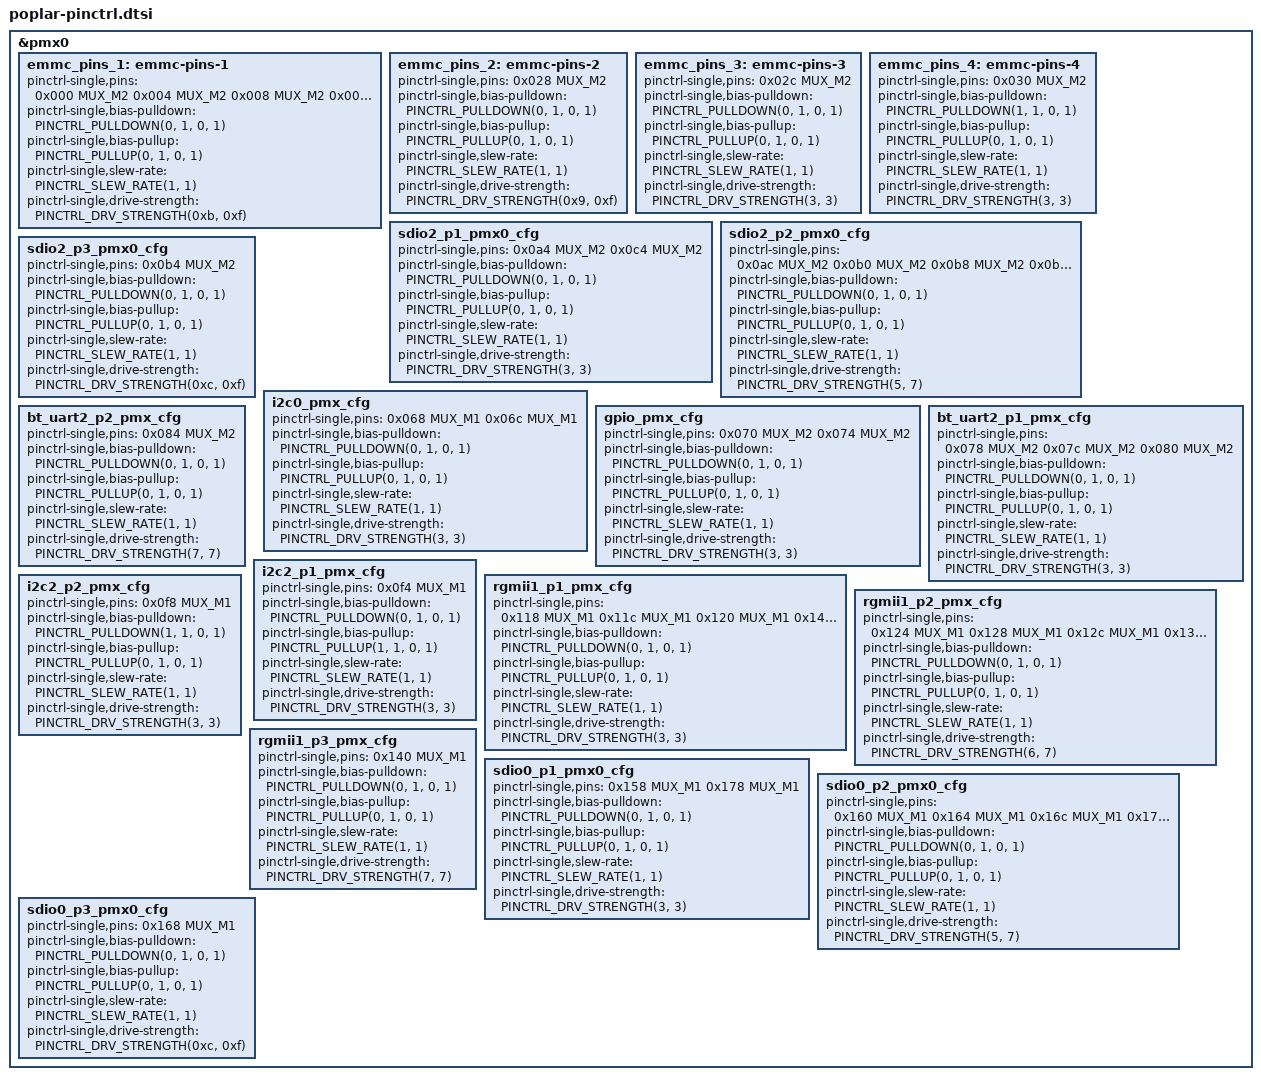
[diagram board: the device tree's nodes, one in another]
// SPDX-License-Identifier: GPL-2.0
/*
 * Pinctrl dts file for HiSilicon Poplar board
 *
 * Copyright (c) 2016-2018 HiSilicon Technologies Co., Ltd.
 */

#include <dt-bindings/pinctrl/hisi.h>

/* value, enable bits, disable bits, mask */
#define PINCTRL_PULLDOWN(value, enable, disable, mask) \
	(value << 13) (enable << 13) (disable << 13) (mask << 13)
#define PINCTRL_PULLUP(value, enable, disable, mask) \
	(value << 12) (enable << 12) (disable << 12) (mask << 12)
#define PINCTRL_SLEW_RATE(value, mask)	  (value << 8) (mask << 8)
#define PINCTRL_DRV_STRENGTH(value, mask) (value << 4) (mask << 4)
#define GPIO5_MUX_CFG(offset, value, bit) (offset) (value << bit) (1 << bit)

&pmx0 {
	emmc_pins_1: emmc-pins-1 {
		pinctrl-single,pins = <
			0x000 MUX_M2
			0x004 MUX_M2
			0x008 MUX_M2
			0x00c MUX_M2
			0x010 MUX_M2
			0x014 MUX_M2
			0x018 MUX_M2
			0x01c MUX_M2
			0x024 MUX_M2
		>;
		pinctrl-single,bias-pulldown = <
			PINCTRL_PULLDOWN(0, 1, 0, 1)
		>;
		pinctrl-single,bias-pullup = <
			PINCTRL_PULLUP(0, 1, 0, 1)
		>;
		pinctrl-single,slew-rate = <
			PINCTRL_SLEW_RATE(1, 1)
		>;
		pinctrl-single,drive-strength = <
			PINCTRL_DRV_STRENGTH(0xb, 0xf)
		>;
	};

	emmc_pins_2: emmc-pins-2 {
		pinctrl-single,pins = <
			0x028 MUX_M2
		>;
		pinctrl-single,bias-pulldown = <
			PINCTRL_PULLDOWN(0, 1, 0, 1)
		>;
		pinctrl-single,bias-pullup = <
			PINCTRL_PULLUP(0, 1, 0, 1)
		>;
		pinctrl-single,slew-rate = <
			PINCTRL_SLEW_RATE(1, 1)
		>;
		pinctrl-single,drive-strength = <
			PINCTRL_DRV_STRENGTH(0x9, 0xf)
		>;
	};

	emmc_pins_3: emmc-pins-3 {
		pinctrl-single,pins = <
			0x02c MUX_M2
		>;
		pinctrl-single,bias-pulldown = <
			PINCTRL_PULLDOWN(0, 1, 0, 1)
		>;
		pinctrl-single,bias-pullup = <
			PINCTRL_PULLUP(0, 1, 0, 1)
		>;
		pinctrl-single,slew-rate = <
			PINCTRL_SLEW_RATE(1, 1)
		>;
		pinctrl-single,drive-strength = <
			PINCTRL_DRV_STRENGTH(3, 3)
		>;
	};

	emmc_pins_4: emmc-pins-4 {
		pinctrl-single,pins = <
			0x030 MUX_M2
		>;
		pinctrl-single,bias-pulldown = <
			PINCTRL_PULLDOWN(1, 1, 0, 1)
		>;
		pinctrl-single,bias-pullup = <
			PINCTRL_PULLUP(0, 1, 0, 1)
		>;
		pinctrl-single,slew-rate = <
			PINCTRL_SLEW_RATE(1, 1)
		>;
		pinctrl-single,drive-strength = <
			PINCTRL_DRV_STRENGTH(3, 3)
		>;
	};

	sdio2_p1_pmx0_cfg: sdio2_p1_pmx0_cfg {
		pinctrl-single,pins = <
			0x0a4 MUX_M2 /* pwren */
			0x0c4 MUX_M2 /* cd */
		>;
		pinctrl-single,bias-pulldown    = <
			PINCTRL_PULLDOWN(0, 1, 0, 1)
		>;
		pinctrl-single,bias-pullup   = <
			PINCTRL_PULLUP(0, 1, 0, 1)
		>;
		pinctrl-single,slew-rate    = <
			PINCTRL_SLEW_RATE(1, 1)
		>;
		pinctrl-single,drive-strength   = <
			PINCTRL_DRV_STRENGTH(3, 3)
		>;
	};

	sdio2_p2_pmx0_cfg: sdio2_p2_pmx0_cfg {
		pinctrl-single,pins = <
			0x0ac MUX_M2
			0x0b0 MUX_M2
			0x0b8 MUX_M2
			0x0bc MUX_M2
			0x0c0 MUX_M2
		>;
		pinctrl-single,bias-pulldown    = <
			PINCTRL_PULLDOWN(0, 1, 0, 1)
		>;
		pinctrl-single,bias-pullup   = <
			PINCTRL_PULLUP(0, 1, 0, 1)
		>;
		pinctrl-single,slew-rate    = <
			PINCTRL_SLEW_RATE(1, 1)
		>;
		pinctrl-single,drive-strength   = <
			PINCTRL_DRV_STRENGTH(5, 7)
		>;
	};

	sdio2_p3_pmx0_cfg: sdio2_p3_pmx0_cfg {
		pinctrl-single,pins = <
			0x0b4 MUX_M2
		>;
		pinctrl-single,bias-pulldown    = <
			PINCTRL_PULLDOWN(0, 1, 0, 1)
		>;
		pinctrl-single,bias-pullup   = <
			PINCTRL_PULLUP(0, 1, 0, 1)
		>;
		pinctrl-single,slew-rate    = <
			PINCTRL_SLEW_RATE(1, 1)
		>;
		pinctrl-single,drive-strength   = <
			PINCTRL_DRV_STRENGTH(0xc, 0xf)
		>;
	};

	i2c0_pmx_cfg: i2c0_pmx_cfg {
		pinctrl-single,pins = <
			0x068 MUX_M1
			0x06c MUX_M1
		>;
		pinctrl-single,bias-pulldown	= <
			PINCTRL_PULLDOWN(0, 1, 0, 1)
		>;
		pinctrl-single,bias-pullup	= <
			PINCTRL_PULLUP(0, 1, 0, 1)
		>;
		pinctrl-single,slew-rate	= <
			PINCTRL_SLEW_RATE(1, 1)
		>;
		pinctrl-single,drive-strength	= <
			PINCTRL_DRV_STRENGTH(3, 3)
		>;
	};

	gpio_pmx_cfg: gpio_pmx_cfg {
		pinctrl-single,pins = <
			0x070 MUX_M2
			0x074 MUX_M2
		>;
		pinctrl-single,bias-pulldown	= <
			PINCTRL_PULLDOWN(0, 1, 0, 1)
		>;
		pinctrl-single,bias-pullup	= <
			PINCTRL_PULLUP(0, 1, 0, 1)
		>;
		pinctrl-single,slew-rate	= <
			PINCTRL_SLEW_RATE(1, 1)
		>;
		pinctrl-single,drive-strength	= <
			PINCTRL_DRV_STRENGTH(3, 3)
		>;
	};

	bt_uart2_p1_pmx_cfg: bt_uart2_p1_pmx_cfg {
		pinctrl-single,pins = <
			0x078 MUX_M2
			0x07c MUX_M2
			0x080 MUX_M2
		>;
		pinctrl-single,bias-pulldown	= <
			PINCTRL_PULLDOWN(0, 1, 0, 1)
		>;
		pinctrl-single,bias-pullup	= <
			PINCTRL_PULLUP(0, 1, 0, 1)
		>;
		pinctrl-single,slew-rate	= <
			PINCTRL_SLEW_RATE(1, 1)
		>;
		pinctrl-single,drive-strength	= <
			PINCTRL_DRV_STRENGTH(3, 3)
		>;
	};

	bt_uart2_p2_pmx_cfg: bt_uart2_p2_pmx_cfg {
		pinctrl-single,pins = <
			0x084 MUX_M2
		>;
		pinctrl-single,bias-pulldown	= <
			PINCTRL_PULLDOWN(0, 1, 0, 1)
		>;
		pinctrl-single,bias-pullup	= <
			PINCTRL_PULLUP(0, 1, 0, 1)
		>;
		pinctrl-single,slew-rate	= <
			PINCTRL_SLEW_RATE(1, 1)
		>;
		pinctrl-single,drive-strength	= <
			PINCTRL_DRV_STRENGTH(7, 7)
		>;
	};

	i2c2_p1_pmx_cfg: i2c2_p1_pmx_cfg {
		pinctrl-single,pins = <
			0x0f4 MUX_M1
		>;
		pinctrl-single,bias-pulldown   = <
			PINCTRL_PULLDOWN(0, 1, 0, 1)
		>;
		pinctrl-single,bias-pullup  = <
			PINCTRL_PULLUP(1, 1, 0, 1)
		>;
		pinctrl-single,slew-rate    = <
			PINCTRL_SLEW_RATE(1, 1)
		>;
		pinctrl-single,drive-strength   = <
			PINCTRL_DRV_STRENGTH(3, 3)
		>;
	};

	i2c2_p2_pmx_cfg: i2c2_p2_pmx_cfg {
		pinctrl-single,pins = <
			0x0f8 MUX_M1
		>;
		pinctrl-single,bias-pulldown   = <
			PINCTRL_PULLDOWN(1, 1, 0, 1)
		>;
		pinctrl-single,bias-pullup  = <
			PINCTRL_PULLUP(0, 1, 0, 1)
		>;
		pinctrl-single,slew-rate    = <
			PINCTRL_SLEW_RATE(1, 1)
		>;
		pinctrl-single,drive-strength   = <
			PINCTRL_DRV_STRENGTH(3, 3)
		>;
	};

	rgmii1_p1_pmx_cfg: rgmii1_p1_pmx_cfg {
		pinctrl-single,pins = <
			0x118 MUX_M1
			0x11c MUX_M1
			0x120 MUX_M1
			0x144 MUX_M1
			0x148 MUX_M1
			0x14c MUX_M1
			0x150 MUX_M1
			0x154 MUX_M1
		>;
		pinctrl-single,bias-pulldown    = <
			PINCTRL_PULLDOWN(0, 1, 0, 1)
		>;
		pinctrl-single,bias-pullup  = <
			PINCTRL_PULLUP(0, 1, 0, 1)
		>;
		pinctrl-single,slew-rate    = <
			PINCTRL_SLEW_RATE(1, 1)
		>;
		pinctrl-single,drive-strength   = <
			PINCTRL_DRV_STRENGTH(3, 3)
		>;
	};

	rgmii1_p2_pmx_cfg: rgmii1_p2_pmx_cfg {
		pinctrl-single,pins = <
			0x124 MUX_M1
			0x128 MUX_M1
			0x12c MUX_M1
			0x130 MUX_M1
			0x134 MUX_M1
			0x13c MUX_M1
		>;
		pinctrl-single,bias-pulldown    = <
			PINCTRL_PULLDOWN(0, 1, 0, 1)
		>;
		pinctrl-single,bias-pullup   = <
			PINCTRL_PULLUP(0, 1, 0, 1)
		>;
		pinctrl-single,slew-rate    = <
			PINCTRL_SLEW_RATE(1, 1)
		>;
		pinctrl-single,drive-strength   = <
			PINCTRL_DRV_STRENGTH(6, 7)
		>;
	};

	rgmii1_p3_pmx_cfg: rgmii1_p3_pmx_cfg {
		pinctrl-single,pins = <
			0x140 MUX_M1
		>;
		pinctrl-single,bias-pulldown    = <
			PINCTRL_PULLDOWN(0, 1, 0, 1)
		>;
		pinctrl-single,bias-pullup   = <
			PINCTRL_PULLUP(0, 1, 0, 1)
		>;
		pinctrl-single,slew-rate    = <
			PINCTRL_SLEW_RATE(1, 1)
		>;
		pinctrl-single,drive-strength   = <
			PINCTRL_DRV_STRENGTH(7, 7)
		>;
	};

	sdio0_p1_pmx0_cfg: sdio0_p1_pmx0_cfg {
		pinctrl-single,pins = <
			0x158 MUX_M1 /* pwren */
			0x178 MUX_M1 /* cd */
		>;
		pinctrl-single,bias-pulldown    = <
			PINCTRL_PULLDOWN(0, 1, 0, 1)
		>;
		pinctrl-single,bias-pullup   = <
			PINCTRL_PULLUP(0, 1, 0, 1)
		>;
		pinctrl-single,slew-rate    = <
			PINCTRL_SLEW_RATE(1, 1)
		>;
		pinctrl-single,drive-strength   = <
			PINCTRL_DRV_STRENGTH(3, 3)
		>;
	};

	sdio0_p2_pmx0_cfg: sdio0_p2_pmx0_cfg {
		pinctrl-single,pins = <
			0x160 MUX_M1 /* D1 */
			0x164 MUX_M1 /* D0 */
			0x16c MUX_M1 /* CMD */
			0x170 MUX_M1 /* D3 */
			0x174 MUX_M1 /* D2 */
		>;
		pinctrl-single,bias-pulldown    = <
			PINCTRL_PULLDOWN(0, 1, 0, 1)
		>;
		pinctrl-single,bias-pullup   = <
			PINCTRL_PULLUP(0, 1, 0, 1)
		>;
		pinctrl-single,slew-rate    = <
			PINCTRL_SLEW_RATE(1, 1)
		>;
		pinctrl-single,drive-strength   = <
			PINCTRL_DRV_STRENGTH(5, 7)
		>;
	};

	sdio0_p3_pmx0_cfg: sdio0_p3_pmx0_cfg {
		pinctrl-single,pins = <
			0x168 MUX_M1 /* CLK */
		>;
		pinctrl-single,bias-pulldown    = <
			PINCTRL_PULLDOWN(0, 1, 0, 1)
		>;
		pinctrl-single,bias-pullup   = <
			PINCTRL_PULLUP(0, 1, 0, 1)
		>;
		pinctrl-single,slew-rate    = <
			PINCTRL_SLEW_RATE(1, 1)
		>;
		pinctrl-single,drive-strength   = <
			PINCTRL_DRV_STRENGTH(0xc, 0xf)
		>;
	};
};

